# UART4 register map
Registers from a debugger description file.
Registers are 32-bit, access not given, no defined reset value unless marked. A register's access mark holds for its fields unless they carry their own. Addresses are absolute; registers are grouped by the start of their names; lines under a group give offsets from that group; [hi:lo] are bit positions; {n}, {i} and the like mark numbered series; 'fields as' and 'values as' point back to an identical list; <NAME> marks a mode.

## UART4
0x50000000 UART4/DLL
  [7:0] DLL
0x50000000 UART4/THR
  [7:0] THR
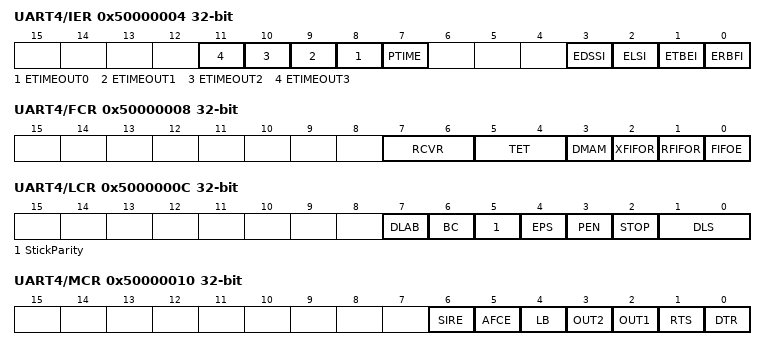
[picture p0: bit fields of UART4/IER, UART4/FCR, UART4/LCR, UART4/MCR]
0x50000004 UART4/IER
  [n+8] ETIMEOUT{n} (n=0..3), [7] PTIME, [3] EDSSI, [2] ELSI, [1] ETBEI, [0] ERBFI
0x50000004 UART4/DLH
  [7:0] DLH
0x50000008 UART4/FCR
  [7:6] RCVR, [5:4] TET, [3] DMAM, [2] XFIFOR, [1] RFIFOR, [0] FIFOE
0x5000000C UART4/LCR
  [7] DLAB, [6] BC, [5] StickParity, [4] EPS, [3] PEN, [2] STOP, [1:0] DLS
0x50000010 UART4/MCR
  [6] SIRE, [5] AFCE, [4] LB, [3] OUT2, [2] OUT1, [1] RTS, [0] DTR
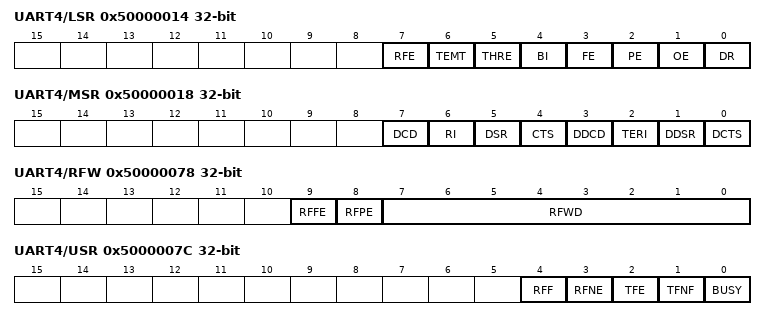
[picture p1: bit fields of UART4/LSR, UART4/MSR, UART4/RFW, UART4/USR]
0x50000014 UART4/LSR ro
  [7] RFE, [6] TEMT, [5] THRE, [4] BI, [3] FE, [2] PE, [1] OE, [0] DR
0x50000018 UART4/MSR ro
  [7] DCD, [6] RI, [5] DSR, [4] CTS, [3] DDCD, [2] TERI, [1] DDSR, [0] DCTS
0x5000001C UART4/SCR
  [7:0] SCR
0x50000030 UART4/STHR
  [7:0] STHR
0x50000070 UART4/FAR
  [0] FAR
0x50000074 UART4/TFR ro
  [7:0] TFR
0x50000078 UART4/RFW
  [9] RFFE, [8] RFPE, [7:0] RFWD
0x5000007C UART4/USR ro
  [4] RFF, [3] RFNE, [2] TFE, [1] TFNF, [0] BUSY
0x50000080 UART4/TFL ro
  [4:0] TFL
0x50000084 UART4/RFL ro
  [4:0] RFL
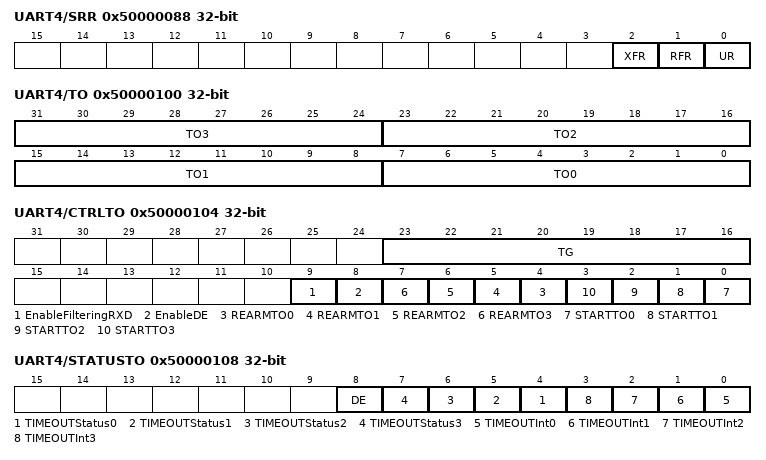
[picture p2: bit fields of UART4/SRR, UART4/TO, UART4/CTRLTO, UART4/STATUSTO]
0x50000088 UART4/SRR
  [2] XFR, [1] RFR, [0] UR
0x5000008C UART4/SRTS
  [0] SRTS
0x50000090 UART4/SBCR
  [0] SBCR
0x50000098 UART4/SFE
  [0] SFE
0x5000009C UART4/SRT
  [1:0] SRCVR
0x500000A0 UART4/STET
  [1:0] STET
0x500000A4 UART4/HTX
  [0] HTX
0x500000A8 UART4/DMASA
  [0] DMASA
0x500000F8 UART4/UCV ro
  [31:0] Version
0x500000FC UART4/CTR ro
  [31:0] ID
0x50000100 UART4/TO
  [8n+7:8n] TO{n} (n=0..3)
0x50000104 UART4/CTRLTO
  [23:16] TG, [9] EnableFilteringRXD, [8] EnableDE, [n+4] REARMTO{n} (n=0..3), [n] STARTTO{n} (n=0..3)
0x50000108 UART4/STATUSTO
  [8] DE, [n+4] TIMEOUTStatus{n} (n=0..3), [n] TIMEOUTInt{n} (n=0..3)
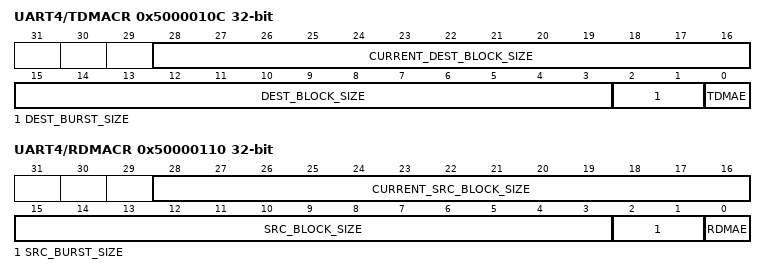
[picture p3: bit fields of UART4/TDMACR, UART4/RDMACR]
0x5000010C UART4/TDMACR
  [28:16] CURRENT_DEST_BLOCK_SIZE, [15:3] DEST_BLOCK_SIZE, [2:1] DEST_BURST_SIZE, [0] TDMAE
0x50000110 UART4/RDMACR
  [28:16] CURRENT_SRC_BLOCK_SIZE, [15:3] SRC_BLOCK_SIZE, [2:1] SRC_BURST_SIZE, [0] RDMAE
